VERSION ""

NS_ :

BS_:

BU_: INV DDC Master Charger
VAL_TABLE_ Prm_Mode 1 "Set Parameter value" 0 "Read back only" ;
VAL_TABLE_ PRM_SelVal 9 "Rectifier mode " 8 "Rectivier limit" 7 "Deadband" 6 "Shift preset value" 5 "Current limits" 4 "Output voltage limits" 3 "Input voltage limits" 2 "Voltage control" 1 "Current control" 0 "Empty" ;
VAL_TABLE_ DCDC_RectModeTab 2 "Rectifier Off" 1 "Rectifier On" 0 "Rectifiermode Auto" ;
VAL_TABLE_ DCDC_FaultSwOffTab 1 "Switchoff due to fault" 0 "Not switched off due to fault" ;
VAL_TABLE_ DCDC_FaultPresenTab 1 "Fault present" 0 "No fault present" ;
VAL_TABLE_ DCDC_SyncRectTab 1 "Sync Rectifier On" 0 "Sync Rectifier Off" ;
VAL_TABLE_ ULv_Plaus 1 "Low voltage plausible" 0 "Low voltage implausible" ;
VAL_TABLE_ TestMode 3 "Don't Care" 2 "HV test Mode" 1 "PCB Test Mode" 0 "Normal Mode" ;
VAL_TABLE_ SupplyState 1 "Supply OK" 0 "Supply not OK" ;
VAL_TABLE_ ShortCircuit 3 "Don't Care" 2 "Negative Short Circuit" 1 "Positive Short Circuit" 0 "No Short Circuit" ;
VAL_TABLE_ ReversePolarity 1 "Reverse Polarity" 0 "No reverse Polarity" ;
VAL_TABLE_ RangeCheck 1 "Ok" 0 "Not Ok" ;
VAL_TABLE_ OvrTempShutDown 1 "Shutdown due to overtemperature" 0 "No overtemperature" ;
VAL_TABLE_ OverVoltageShutDown 1 "Shutdown due to overvoltage" 0 "No overvoltage" ;
VAL_TABLE_ OverCurrentShutDown 1 "Shutdown due to overcurrent" 0 "No overcurrent" ;
VAL_TABLE_ OpMode 7 "Failure" 6 "Reserve4" 5 "Reserve3" 4 "Reserve2" 3 "Reserve1" 2 "Buck" 1 "Standby" 0 "Init" ;
VAL_TABLE_ InitFail_9Bit 511 "Failure" 510 "Init" ;
VAL_TABLE_ InitFail_11Bit 2047 "Failure" 2046 "Init" ;
VAL_TABLE_ InitFail_10Bit 1023 "Failure" 1022 "Init" ;
VAL_TABLE_ FullBridgeEnable 1 "Full Bridge Switched on" 0 "Full Bridge Switched off" ;
VAL_TABLE_ ErrorSupplyVoltage 1 "Error Supply Voltage" 0 "Supply Voltage O.K." ;
VAL_TABLE_ EnOutp 3 "EnLvOutBuck=1; EnLvOutBoost=1" 2 "EnLvOutBuck=1; EnLvOutBoost=0" 1 "EnLvOutBuck=0; EnLvOutBoost=1" 0 "EnLvOutBuck=0; EnLvOutBoost=0" ;
VAL_TABLE_ EnLvOut 1 "Active (closed)" 0 "Inactive (open)" ;
VAL_TABLE_ DesMode 3 "Reserve2" 2 "GoReset" 1 "Buck" 0 "Standby" ;
VAL_TABLE_ ControlMode 1 "Current Control active" 0 "Voltage Control active" ;
VAL_TABLE_ SucEnable 1 "turn SUC on" 0 "turn SUC off" ;
VAL_TABLE_ DCDCMode 2 "Steuerung_Vorgabewert" 1 "Regelung_Aktiv" 0 "Standby" ;

BO_ 3221225472 VECTOR__INDEPENDENT_SIG_MSG: 0 Vector__XXX
 SG_ PRM_Dummy4 : 0|16@1- (1,0) [0|0] "" Vector__XXX
 SG_ PRM_Dummy3 : 0|16@1- (1,0) [0|0] "" Vector__XXX
 SG_ StaMsgCntr : 0|8@1+ (1,0) [0|255] "" Vector__XXX
 SG_ PRM_enaSynRectOvlp : 0|8@1+ (1,0) [0|40] "setBit_to_enable_Fault" Vector__XXX
 SG_ PRM_numSynRectOvlp2 : 0|8@1+ (1,0) [0|40] "setBit_to_enable_Fault" Vector__XXX
 SG_ Parameter2 : 0|16@1- (1,0) [0|0] "" Vector__XXX
 SG_ Parameter1 : 0|16@1- (1,0) [0|0] "" Vector__XXX

BO_ 293 DDC_12: 8 DDC
 SG_ DDC_Suc_Fail : 27|1@1+ (1,0) [0|1] ""  INV
 SG_ DDC_IHv : 32|10@1+ (0.025,0) [0|25.575] "A"  INV
 SG_ DDC_UHv_Overvoltage : 26|1@1+ (1,0) [0|1] ""  INV
 SG_ DDC_UHv_Undervoltage : 25|1@1+ (1,0) [0|1] ""  INV
 SG_ DDC_HvOverCurrent : 24|1@1+ (1,0) [0|1] ""  INV
 SG_ DDC_RangeChk_VZK_UBat : 23|1@1+ (1,0) [0|1] ""  INV
 SG_ DDC_RangeChk_VZK_LoRng : 22|1@1+ (1,0) [0|1] ""  INV
 SG_ DDC_RangeChk_VZK_HiRng : 21|1@1+ (1,0) [0|1] ""  INV
 SG_ DDC_RangeChk_VZK_Gnd : 20|1@1+ (1,0) [0|1] ""  INV
 SG_ DDC_RangeChk_IZK_UBat : 19|1@1+ (1,0) [0|1] ""  INV
 SG_ DDC_RangeChk_IZK_LoRng : 18|1@1+ (1,0) [0|1] ""  INV
 SG_ DDC_RangeChk_IZK_HiRng : 17|1@1+ (1,0) [0|1] ""  INV
 SG_ DDC_RangeChk_IZK_Gnd : 16|1@1+ (1,0) [0|1] ""  INV
 SG_ DDC_RangeChk_VLV_UBat : 15|1@1+ (1,0) [0|1] ""  INV
 SG_ DDC_RangeChk_VLV_LoRng : 14|1@1+ (1,0) [0|1] ""  INV
 SG_ DDC_RangeChk_VLV_HiRng : 13|1@1+ (1,0) [0|1] ""  INV
 SG_ DDC_RangeChk_VLV_Gnd : 12|1@1+ (1,0) [0|1] ""  INV
 SG_ DDC_RangeChk_VHV_UBat : 11|1@1+ (1,0) [0|1] ""  INV
 SG_ DDC_RangeChk_VHV_LoRng : 10|1@1+ (1,0) [0|1] ""  INV
 SG_ DDC_RangeChk_VHV_HiRng : 9|1@1+ (1,0) [0|1] ""  INV
 SG_ DDC_RangeChk_VHV_Gnd : 8|1@1+ (1,0) [0|1] ""  INV
 SG_ DDC_RangeChk_ILV_UBat : 7|1@1+ (1,0) [0|1] ""  INV
 SG_ DDC_RangeChk_ILV_LoRng : 6|1@1+ (1,0) [0|1] ""  INV
 SG_ DDC_RangeChk_ILV_HiRng : 5|1@1+ (1,0) [0|1] ""  INV
 SG_ DDC_RangeChk_ILV_Gnd : 4|1@1+ (1,0) [0|1] ""  INV
 SG_ DDC_RangeChk_IHV_UBat : 3|1@1+ (1,0) [0|1] ""  INV
 SG_ DDC_RangeChk_IHV_LoRng : 2|1@1+ (1,0) [0|1] ""  INV
 SG_ DDC_RangeChk_IHV_HiRng : 1|1@1+ (1,0) [0|1] ""  INV
 SG_ DDC_RangeChk_IHV_Gnd : 0|1@1+ (1,0) [0|1] ""  INV

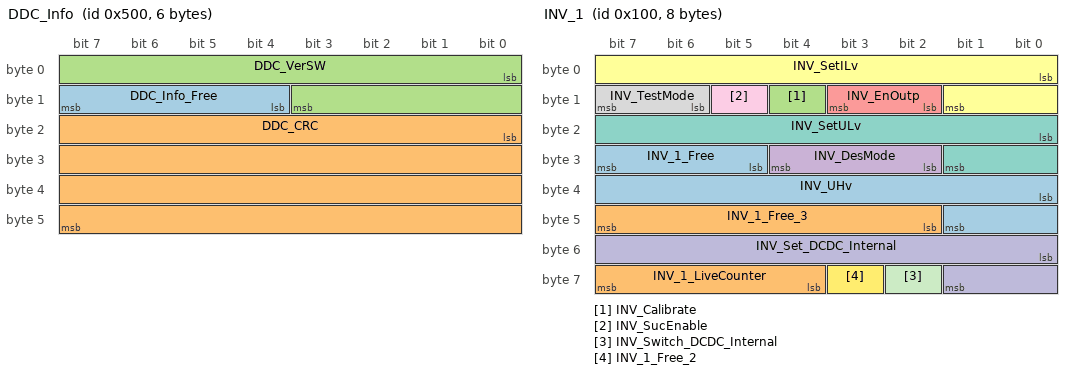
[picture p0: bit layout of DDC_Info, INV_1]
BO_ 1280 DDC_Info: 6 DDC
 SG_ DDC_Info_Free : 12|4@1+ (1,0) [0|15] ""  INV
 SG_ DDC_CRC : 16|32@1+ (1,0) [0|4294967295] ""  INV
 SG_ DDC_VerSW : 0|12@1+ (1,0) [0|4095] ""  INV

BO_ 256 INV_1: 8 INV
 SG_ INV_1_Free : 29|3@1+ (1,0) [0|7] ""  DDC
 SG_ INV_1_LiveCounter : 60|4@1+ (1,0) [0|15] ""  DDC
 SG_ INV_Calibrate : 12|1@1+ (1,0) [0|0] ""  DDC
 SG_ INV_DesMode : 26|3@1+ (1,0) [0|7] ""  DDC
 SG_ INV_EnOutp : 10|2@1+ (1,0) [0|3] ""  DDC
 SG_ INV_SetILv : 0|10@1+ (0.25,0) [0|255.75] "A"  DDC
 SG_ INV_SetULv : 16|10@1+ (0.015625,4) [4|19.984375] "V"  DDC
 SG_ INV_TestMode : 14|2@1+ (1,0) [0|3] ""  DDC
 SG_ INV_SucEnable : 13|1@1+ (1,0) [0|1] ""  DDC
 SG_ INV_Set_DCDC_Internal : 48|10@1+ (1,0) [0|1023] ""  DDC
 SG_ INV_Switch_DCDC_Internal : 58|1@1+ (1,0) [0|1] ""  DDC
 SG_ INV_1_Free_2 : 59|1@1+ (1,0) [0|1] ""  DDC
 SG_ INV_UHv : 32|10@1+ (0.5,0) [0|511.5] ""  DDC
 SG_ INV_1_Free_3 : 42|6@1+ (1,0) [0|63] ""  DDC

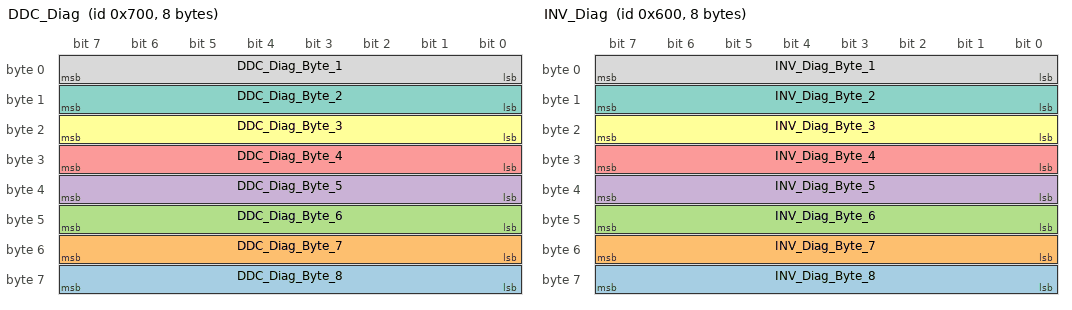
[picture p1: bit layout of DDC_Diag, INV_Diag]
BO_ 1792 DDC_Diag: 8 DDC
 SG_ DDC_Diag_Byte_8 : 56|8@1+ (1,0) [0|255] ""  INV
 SG_ DDC_Diag_Byte_7 : 48|8@1+ (1,0) [0|255] ""  INV
 SG_ DDC_Diag_Byte_6 : 40|8@1+ (1,0) [0|255] ""  INV
 SG_ DDC_Diag_Byte_5 : 32|8@1+ (1,0) [0|255] ""  INV
 SG_ DDC_Diag_Byte_4 : 24|8@1+ (1,0) [0|255] ""  INV
 SG_ DDC_Diag_Byte_3 : 16|8@1+ (1,0) [0|255] ""  INV
 SG_ DDC_Diag_Byte_2 : 8|8@1+ (1,0) [0|255] ""  INV
 SG_ DDC_Diag_Byte_1 : 0|8@1+ (1,0) [0|255] ""  INV

BO_ 1536 INV_Diag: 8 INV
 SG_ INV_Diag_Byte_8 : 56|8@1+ (1,0) [0|255] ""  DDC
 SG_ INV_Diag_Byte_7 : 48|8@1+ (1,0) [0|255] ""  DDC
 SG_ INV_Diag_Byte_6 : 40|8@1+ (1,0) [0|255] ""  DDC
 SG_ INV_Diag_Byte_5 : 32|8@1+ (1,0) [0|255] ""  DDC
 SG_ INV_Diag_Byte_4 : 24|8@1+ (1,0) [0|255] ""  DDC
 SG_ INV_Diag_Byte_3 : 16|8@1+ (1,0) [0|255] ""  DDC
 SG_ INV_Diag_Byte_2 : 8|8@1+ (1,0) [0|255] ""  DDC
 SG_ INV_Diag_Byte_1 : 0|8@1+ (1,0) [0|255] ""  DDC

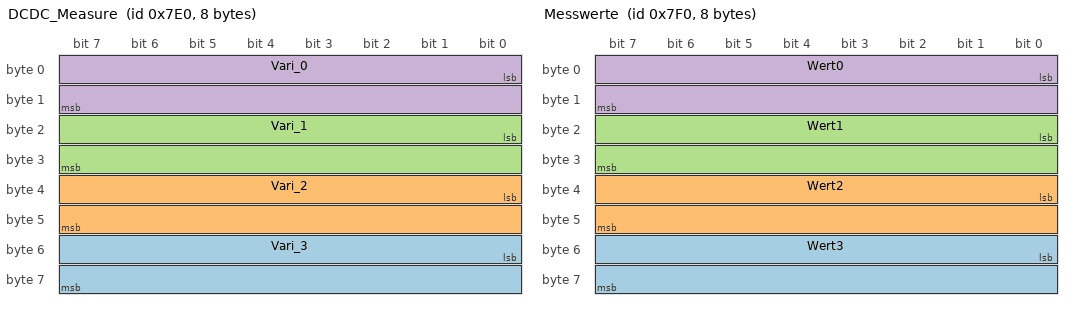
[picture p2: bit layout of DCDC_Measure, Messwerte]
BO_ 2016 DCDC_Measure: 8 Vector__XXX
 SG_ Vari_3 : 48|16@1- (1,0) [0|0] "" Vector__XXX
 SG_ Vari_2 : 32|16@1- (1,0) [0|0] "" Vector__XXX
 SG_ Vari_1 : 16|16@1- (1,0) [0|0] "" Vector__XXX
 SG_ Vari_0 : 0|16@1- (1,0) [0|0] "" Vector__XXX

BO_ 288 DDC_11: 8 DDC
 SG_ DDC_LiveCounter_Error : 46|1@1+ (1,0) [0|1] ""  INV
 SG_ DDC_CAN_Tout : 45|1@1+ (1,0) [0|1] ""  INV
 SG_ DDC_Int_Fail_Cause : 47|1@1+ (1,0) [0|1] ""  INV
 SG_ DDC_DCDC_Shutdown : 43|2@1+ (1,0) [0|3] ""  INV
 SG_ DDC_FB_Overload : 42|1@1+ (1,0) [0|1] ""  INV
 SG_ DDC_ControlMode : 62|1@1+ (1,0) [0|1] ""  INV
 SG_ DDC_HV_Serial_Data_ok : 30|1@1+ (1,0) [0|1] ""  INV
 SG_ DDC_LnkOverVoltage : 63|1@1+ (1,0) [0|1] ""  INV
 SG_ DDC_LV_Serial_Data_ok : 29|1@1+ (1,0) [0|1] ""  INV
 SG_ DDC_ScrewExist : 61|1@1+ (1,0) [0|1] ""  INV
 SG_ DDC_OvrTempShutDown : 60|1@1+ (1,0) [0|1] ""  INV
 SG_ DDC_ULnk : 32|10@1+ (0.5,0) [0|511.5] "V"  INV
 SG_ DDC_SetULv : 16|10@1+ (0.015625,0) [0|15.984375] "V"  INV
 SG_ DDC_SetILv : 0|10@1+ (0.25,0) [0|255.75] "A"  INV
 SG_ DDC_ReversePolarity : 31|1@1+ (1,0) [0|1] ""  INV
 SG_ DDC_ResetFinish : 28|1@1+ (1,0) [0|1] ""  INV
 SG_ DDC_LV_S8_13V : 11|1@1+ (1,0) [0|1] ""  INV
 SG_ DDC_LV_S7_13V : 10|1@1+ (1,0) [0|1] ""  INV
 SG_ DDC_LV_3V3 : 13|1@1+ (1,0) [0|1] ""  INV
 SG_ DDC_LV_13V : 12|1@1+ (1,0) [0|1] ""  INV
 SG_ DDC_ILnk : 48|10@1+ (0.025,0) [0|25.575] "A"  INV
 SG_ DDC_HV_3V3 : 15|1@1+ (1,0) [0|1] ""  INV
 SG_ DDC_HV_13V_FB : 14|1@1+ (1,0) [0|1] ""  INV
 SG_ DDC_HV_13V_Boost : 26|1@1+ (1,0) [0|1] ""  INV
 SG_ DDC_HV_13V : 27|1@1+ (1,0) [0|1] ""  INV
 SG_ DDC_FBEnable : 58|1@1+ (1,0) [0|1] ""  INV
 SG_ DDC_SucEnable : 59|1@1+ (1,0) [0|1] ""  INV

BO_ 2032 Messwerte: 8 Vector__XXX
 SG_ Wert3 : 48|16@1- (1,0) [0|0] "" Vector__XXX
 SG_ Wert2 : 32|16@1- (1,0) [0|0] "" Vector__XXX
 SG_ Wert1 : 16|16@1- (1,0) [0|0] "" Vector__XXX
 SG_ Wert0 : 0|16@1- (1,0) [0|0] "" Vector__XXX

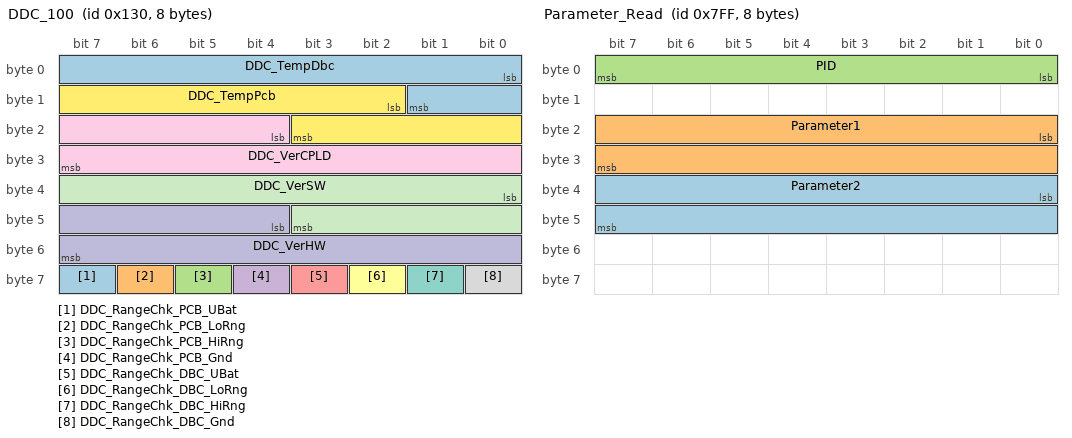
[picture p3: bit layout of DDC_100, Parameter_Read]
BO_ 304 DDC_100: 8 DDC
 SG_ DDC_RangeChk_PCB_UBat : 63|1@1+ (1,0) [0|1] ""  INV
 SG_ DDC_RangeChk_PCB_LoRng : 62|1@1+ (1,0) [0|1] ""  INV
 SG_ DDC_RangeChk_PCB_HiRng : 61|1@1+ (1,0) [0|1] ""  INV
 SG_ DDC_RangeChk_PCB_Gnd : 60|1@1+ (1,0) [0|1] ""  INV
 SG_ DDC_RangeChk_DBC_UBat : 59|1@1+ (1,0) [0|1] ""  INV
 SG_ DDC_RangeChk_DBC_LoRng : 58|1@1+ (1,0) [0|1] ""  INV
 SG_ DDC_RangeChk_DBC_HiRng : 57|1@1+ (1,0) [0|1] ""  INV
 SG_ DDC_RangeChk_DBC_Gnd : 56|1@1+ (1,0) [0|1] ""  INV
 SG_ DDC_VerCPLD : 20|12@1+ (1,0) [0|4095] ""  INV
 SG_ DDC_VerHW : 44|12@1+ (1,0) [0|4095] ""  INV
 SG_ DDC_VerSW : 32|12@1+ (1,0) [0|4095] ""  INV
 SG_ DDC_TempPcb : 10|10@1+ (0.25,-50) [-50|205.75] "°C"  INV
 SG_ DDC_TempDbc : 0|10@1+ (0.25,-50) [-50|205.75] "°C"  INV

BO_ 2047 Parameter_Read: 8 Vector__XXX
 SG_ Parameter2 : 32|16@1- (1,0) [0|0] "" Vector__XXX
 SG_ Parameter1 : 16|16@1- (1,0) [0|0] "" Vector__XXX
 SG_ PID : 0|8@1+ (1,0) [0|0] "" Vector__XXX

BO_ 2046 Parameter_Write: 8 Vector__XXX
 SG_ PRM_frqJitter m10 : 16|16@1- (1,0) [0|10000] "Hz" Vector__XXX
 SG_ PRM_ampJitter m10 : 32|16@1- (1,0) [0|10] "%" Vector__XXX
 SG_ PRM_Rect_Mode m9 : 16|16@1- (1,0) [-32768|32767] "" Vector__XXX
 SG_ PRM_PhaseShiftDCDC m6 : 16|16@1- (0.02442,0) [0|100] "%" Vector__XXX
 SG_ PRM_uOutMin m4 : 16|16@1- (0.03125,0) [0|600] "V" Vector__XXX
 SG_ PRM_uOutMax m4 : 32|16@1- (0.03125,0) [0|600] "V" Vector__XXX
 SG_ PRM_uInputMin m3 : 32|16@1- (0.03125,0) [0|600] "V" Vector__XXX
 SG_ PRM_uInputMax m3 : 16|16@1- (0.03125,0) [0|600] "V" Vector__XXX
 SG_ PRM_numSynRectOfs m6 : 32|16@1+ (1,0) [0|65535] "ticks" Vector__XXX
 SG_ PRM_numDeadOnBase m7 : 16|16@1- (8.3,0) [-271974.4|271966.1] "ns" Vector__XXX
 SG_ PRM_numDeadOffBase m7 : 32|16@1- (8.3,0) [-271974.4|271966.1] "ns" Vector__XXX
 SG_ PRM_iHVPeakDCDC m5 : 16|16@1- (0.00564,0) [0|20] "A" Vector__XXX
 SG_ PRM_iOutMax m5 : 32|16@1- (0.003906,0) [0|20] "A" Vector__XXX
 SG_ PRM_Curr_Rect_On m8 : 16|16@1- (0.003906,0) [0|100] "A" Vector__XXX
 SG_ PRM_Curr_Rect_Off m8 : 32|16@1- (0.003906,0) [0|100] "A" Vector__XXX
 SG_ PRM_Curr_Peak_Ofs m9 : 32|16@1- (0.0009765,0) [-31.997952|31.9969755] "A" Vector__XXX
 SG_ PRM_facHVDCDCVltgCtlProp m2 : 16|16@1- (0.00024414,0) [-7.99997952|7.99973538] "AperV" Vector__XXX
 SG_ PRM_facHVDCDCVltgCtlIntg m2 : 32|16@1- (0.00024414,0) [-7.99997952|7.99973538] "AperVms" Vector__XXX
 SG_ PRM_facHVDCDCCurrCtlProp m1 : 16|16@1- (0.00024414,0) [-7.99997952|7.99973538] "AperA" Vector__XXX
 SG_ PRM_facHVDCDCCurrCtlIntg m1 : 32|16@1- (0.00024414,0) [-7.99997952|7.99973538] "AperAms" Vector__XXX
 SG_ PRM_Dummy2 m0 : 32|16@1- (1,0) [0|0] "" Vector__XXX
 SG_ PRM_Dummy1 m0 : 16|16@1- (1,0) [0|0] "" Vector__XXX
 SG_ ParameterMode : 8|8@1+ (1,0) [0|0] "" Vector__XXX
 SG_ PID M : 0|8@1+ (1,0) [0|0] "" Vector__XXX

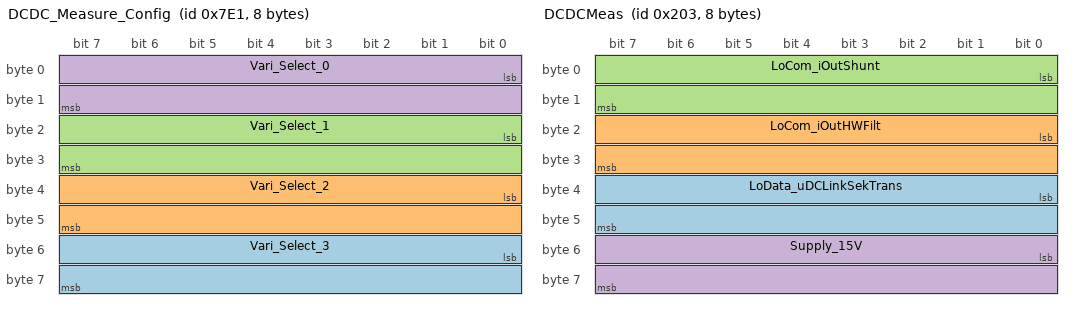
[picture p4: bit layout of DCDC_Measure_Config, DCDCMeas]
BO_ 2017 DCDC_Measure_Config: 8 Master
 SG_ Vari_Select_3 : 48|16@1+ (1,0) [0|0] "" Vector__XXX
 SG_ Vari_Select_2 : 32|16@1+ (1,0) [0|0] "" Vector__XXX
 SG_ Vari_Select_1 : 16|16@1+ (1,0) [0|0] "" Vector__XXX
 SG_ Vari_Select_0 : 0|16@1+ (1,0) [0|0] "" Vector__XXX

BO_ 515 DCDCMeas: 8 Charger
 SG_ LoData_uDCLinkSekTrans : 32|16@1- (0.03125,0) [-1024|1023.96875] "V" Vector__XXX
 SG_ LoCom_iOutHWFilt : 16|16@1- (0.0078125,0) [-256|255.9921875] "A" Vector__XXX
 SG_ LoCom_iOutShunt : 0|16@1- (0.0078125,0) [-256|255.9921875] "A" Vector__XXX
 SG_ Supply_15V : 48|16@1- (0.0089285714285714,0) [-292.57142857143|292.5625] "V" Vector__XXX

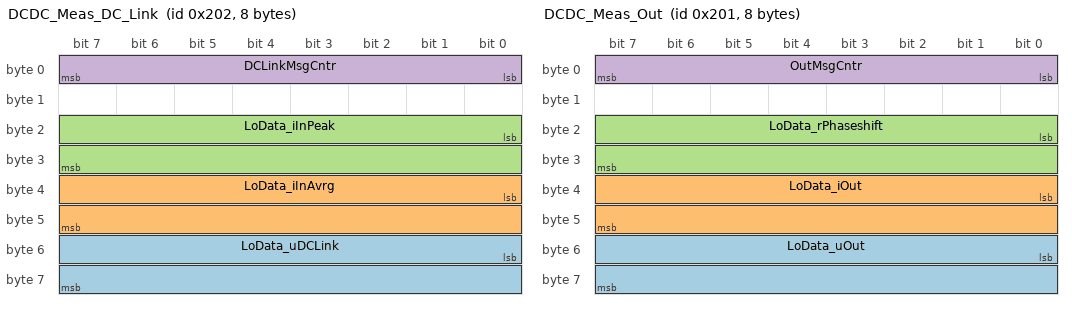
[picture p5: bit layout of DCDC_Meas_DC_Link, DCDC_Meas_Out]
BO_ 514 DCDC_Meas_DC_Link: 8 Charger
 SG_ LoData_uDCLink : 48|16@1- (0.03125,0) [-1024|1023.96875] "V" Vector__XXX
 SG_ LoData_iInAvrg : 32|16@1- (0.0009765625,0) [-32|31.9990234375] "A" Vector__XXX
 SG_ LoData_iInPeak : 16|16@1- (0.0009765625,0) [-32|31.9990234375] "A" Vector__XXX
 SG_ DCLinkMsgCntr : 0|8@1+ (1,0) [0|255] "" Vector__XXX

BO_ 513 DCDC_Meas_Out: 8 Charger
 SG_ LoData_uOut : 48|16@1- (0.016,0) [-524.288|524.272] "V" Vector__XXX
 SG_ LoData_iOut : 32|16@1- (0.0078125,0) [-256|255.9921875] "A" Vector__XXX
 SG_ LoData_rPhaseshift : 16|16@1- (0.0244140625,0) [-800|799.9755859375] "%" Vector__XXX
 SG_ OutMsgCntr : 0|8@1+ (1,0) [0|255] "" Vector__XXX

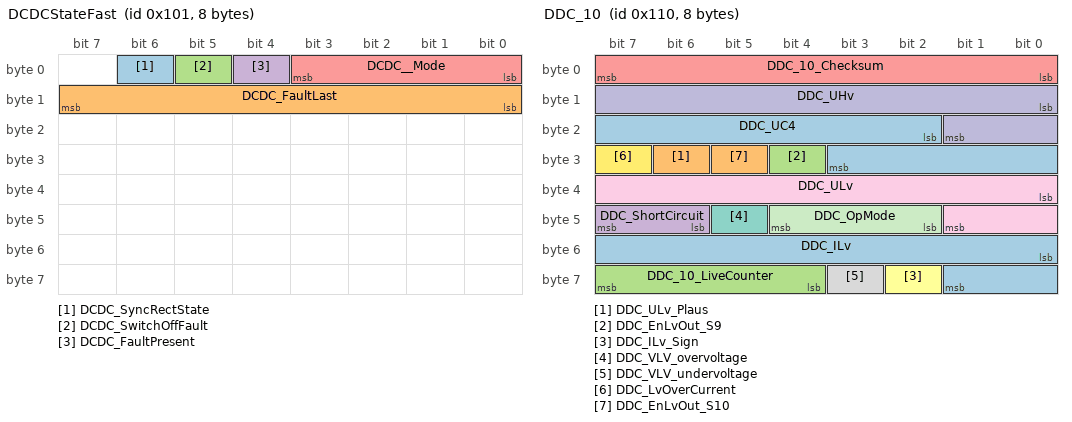
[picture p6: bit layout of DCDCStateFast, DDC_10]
BO_ 257 DCDCStateFast: 8 Charger
 SG_ DCDC_SyncRectState : 6|1@1+ (1,0) [0|0] "" Vector__XXX
 SG_ DCDC_FaultLast : 8|8@1- (1,0) [0|0] "" Vector__XXX
 SG_ DCDC_SwitchOffFault : 5|1@1+ (1,0) [0|0] "" Vector__XXX
 SG_ DCDC_FaultPresent : 4|1@1+ (1,0) [0|0] "" Vector__XXX
 SG_ DCDC__Mode : 0|4@1+ (1,0) [0|15] "" Vector__XXX

BO_ 272 DDC_10: 8 DDC
 SG_ DDC_UC4 : 18|10@1+ (0.03125,0) [0|31.96875] "V"  INV
 SG_ DDC_ULv_Plaus : 30|1@1+ (1,0) [0|1] ""  INV
 SG_ DDC_EnLvOut_S9 : 28|1@1+ (1,0) [0|1] ""  INV
 SG_ DDC_ShortCircuit : 46|2@1+ (1,0) [0|3] ""  INV
 SG_ DDC_10_Checksum : 0|8@1+ (1,0) [0|255] ""  INV
 SG_ DDC_ILv_Sign : 58|1@1+ (1,0) [0|1] ""  INV
 SG_ DDC_VLV_overvoltage : 45|1@1+ (1,0) [0|1] ""  INV
 SG_ DDC_VLV_undervoltage : 59|1@1+ (1,0) [0|1] ""  INV
 SG_ DDC_ULv : 32|10@1+ (0.03125,0) [0|31.96875] "V"  INV
 SG_ DDC_UHv : 8|10@1+ (0.5,0) [0|511.5] "V"  INV
 SG_ DDC_OpMode : 42|3@1+ (1,0) [0|7] ""  INV
 SG_ DDC_LvOverCurrent : 31|1@1+ (1,0) [0|1] ""  INV
 SG_ DDC_ILv : 48|10@1+ (0.25,0) [0|255.75] "A"  INV
 SG_ DDC_EnLvOut_S10 : 29|1@1+ (1,0) [0|1] ""  INV
 SG_ DDC_10_LiveCounter : 60|4@1+ (1,0) [0|15] ""  INV

EV_ HV_Act_Val_In: 0 [0|1] "V" 0 1 DUMMY_NODE_VECTOR0 Vector__XXX;

EV_ UMG_DDC_EnLvOut: 0 [0|1] "" 0 2 DUMMY_NODE_VECTOR0 Vector__XXX;

CM_ BO_ 3221225472 "This is a message for not used signals, created by Vector CANdb++ DBC OLE DB Provider.";
CM_ SG_ 293 DDC_Suc_Fail "Specifies whether Step Up Converter is malfunctioning.";
CM_ SG_ 293 DDC_IHv "Reports the actual current on the HV side (shunt RS2).";
CM_ SG_ 293 DDC_UHv_Overvoltage "indicates status of VZK RangeCheck
detects connection to Ground";
CM_ SG_ 293 DDC_UHv_Undervoltage "indicates status of VZK RangeCheck
detects connection to Ground";
CM_ SG_ 293 DDC_HvOverCurrent "Indicates an over current on the HV side of the DC/DC-converter";
CM_ SG_ 293 DDC_RangeChk_VZK_UBat "indicates status of VZK RangeCheck
detects connection to U Batt (supply voltage)";
CM_ SG_ 293 DDC_RangeChk_VZK_LoRng "indicates status of VZK RangeCheck
detects physical values which are below the feasible range";
CM_ SG_ 293 DDC_RangeChk_VZK_HiRng "indicates status of VZK RangeCheck
detects physical values which are above the feasible range";
CM_ SG_ 293 DDC_RangeChk_VZK_Gnd "indicates status of VZK RangeCheck
detects connection to Ground";
CM_ SG_ 293 DDC_RangeChk_IZK_UBat "indicates status of IRS3 RangeCheck
detects connection to U Batt (supply voltage)";
CM_ SG_ 293 DDC_RangeChk_IZK_LoRng "indicates status of IRS3 RangeCheck
detects physical values which are below the feasible range";
CM_ SG_ 293 DDC_RangeChk_IZK_HiRng "indicates status of IRS3 RangeCheck
detects physical values which are above the feasible range";
CM_ SG_ 293 DDC_RangeChk_IZK_Gnd "indicates status of IRS3 RangeCheck
detects connection to Ground";
CM_ SG_ 293 DDC_RangeChk_VLV_UBat "indicates status of VLV RangeCheck
detects connection to U Batt (supply voltage)";
CM_ SG_ 293 DDC_RangeChk_VLV_LoRng "indicates status of VLV RangeCheck
detects physical values which are below the feasible range";
CM_ SG_ 293 DDC_RangeChk_VLV_HiRng "indicates status of VLV RangeCheck
detects physical values which are above the feasible range";
CM_ SG_ 293 DDC_RangeChk_VLV_Gnd "indicates status of VLV RangeCheck
detects connection to Ground";
CM_ SG_ 293 DDC_RangeChk_VHV_UBat "indicates status of VHV RangeCheck
detects connection to U Batt (supply voltage)";
CM_ SG_ 293 DDC_RangeChk_VHV_LoRng "indicates status of VHV RangeCheck
detects physical values which are below the feasible range";
CM_ SG_ 293 DDC_RangeChk_VHV_HiRng "indicates status of VHV RangeCheck
detects physical values which are above the feasible range";
CM_ SG_ 293 DDC_RangeChk_VHV_Gnd "indicates status of VHV RangeCheck
detects connection to Ground";
CM_ SG_ 293 DDC_RangeChk_ILV_UBat "indicates status of ILV RangeCheck
detects connection to U Batt (supply voltage)";
CM_ SG_ 293 DDC_RangeChk_ILV_LoRng "indicates status of ILV RangeCheck
detects physical values which are below the feasible range";
CM_ SG_ 293 DDC_RangeChk_ILV_HiRng "indicates status of ILV RangeCheck
detects physical values which are above the feasible range";
CM_ SG_ 293 DDC_RangeChk_ILV_Gnd "indicates status of ILV RangeCheck
detects connection to Ground";
CM_ SG_ 293 DDC_RangeChk_IHV_UBat "indicates status of IHV RangeCheck
detects connection to U Batt (supply voltage)";
CM_ SG_ 293 DDC_RangeChk_IHV_LoRng "indicates status of IHV RangeCheck
detects physical values which are below the feasible range";
CM_ SG_ 293 DDC_RangeChk_IHV_HiRng "indicates status of IHV RangeCheck
detects physical values which are above the feasible range";
CM_ SG_ 293 DDC_RangeChk_IHV_Gnd "indicates status of IHV RangeCheck
detects connection to Ground";
CM_ SG_ 1280 DDC_CRC "CRC checksum of µC LV software";
CM_ SG_ 1280 DDC_VerSW "2 MSB bits (Bits 11-10) :
00 - B sample
01 - C sample
10 - D sample
11 - Not used
Example :
Version Number B 1.0.0 -> 00 001 000 0000
                          C 3.2.5 -> 01 011 010 0101
";
CM_ SG_ 256 INV_1_Free "Free for DCDC Internal Testing";
CM_ SG_ 256 INV_1_LiveCounter "To check internal communication
Every new message should increment this counter by 1 and wrap to '0' when counter is equal to 15";
CM_ SG_ 256 INV_Calibrate "Calibrate Measurement Signals based on special Working Point

0 to 1- Calibrate

1 to 0 - Don't Care
";
CM_ SG_ 256 INV_DesMode "Desired operating mode the DC/DC converter.";
CM_ SG_ 256 INV_EnOutp "Used to control the transistors S9 (ENLVOUTBOOST) and S10 (ENLVOUTBUCK).";
CM_ SG_ 256 INV_SetILv "Current limit on the LV side.";
CM_ SG_ 256 INV_SetULv "Set point voltage on the LV side.";
CM_ SG_ 256 INV_TestMode "To switch between different modes (Normal Mode, Test Mode PCB, Test Mode HV)
00 - Normal Mode
01 - PCB Test Mode
10 - HV test Mode
11 - Don't Care";
CM_ SG_ 256 INV_SucEnable "activate Step Up Converter";
CM_ SG_ 256 INV_Set_DCDC_Internal "Current limit on the LV side.";
CM_ SG_ 256 INV_Switch_DCDC_Internal "0 - Manual Calculation
1 - Use Valiue coming over CAN";
CM_ SG_ 256 INV_1_Free_2 "Free for DCDC Internal Testing";
CM_ SG_ 256 INV_UHv "Inverter reports the actual voltage on the HV side";
CM_ SG_ 256 INV_1_Free_3 "Free for DCDC Internal Testing";
CM_ SG_ 1792 DDC_Diag_Byte_8 "Diag Frame byte8";
CM_ SG_ 1792 DDC_Diag_Byte_7 "Diag Frame byte7";
CM_ SG_ 1792 DDC_Diag_Byte_6 "Diag Frame byte6";
CM_ SG_ 1792 DDC_Diag_Byte_5 "Diag Frame byte5";
CM_ SG_ 1792 DDC_Diag_Byte_4 "Diag Frame byte4";
CM_ SG_ 1792 DDC_Diag_Byte_3 "Diag Frame byte3";
CM_ SG_ 1792 DDC_Diag_Byte_2 "Diag Frame byte2";
CM_ SG_ 1792 DDC_Diag_Byte_1 "Diag Frame byte1";
CM_ SG_ 1536 INV_Diag_Byte_8 "Diag Frame byte8";
CM_ SG_ 1536 INV_Diag_Byte_7 "Diag Frame byte7";
CM_ SG_ 1536 INV_Diag_Byte_6 "Diag Frame byte6";
CM_ SG_ 1536 INV_Diag_Byte_5 "Diag Frame byte5";
CM_ SG_ 1536 INV_Diag_Byte_4 "Diag Frame byte4";
CM_ SG_ 1536 INV_Diag_Byte_3 "Diag Frame byte3";
CM_ SG_ 1536 INV_Diag_Byte_2 "Diag Frame byte2";
CM_ SG_ 1536 INV_Diag_Byte_1 "Diag Frame byte1";
CM_ SG_ 288 DDC_LiveCounter_Error "indicates live counter error in INV_1";
CM_ SG_ 288 DDC_CAN_Tout "indicates CAN C time out reported by DCDC converter";
CM_ SG_ 288 DDC_Int_Fail_Cause "Specifies Internal faliure causes for DCDC. At present it is not used. In future value description table is added according to needs";
CM_ SG_ 288 DDC_DCDC_Shutdown "Specifies whether LVuC, LV CPLD or HV CPLD detected failure and switched failure/standby mode";
CM_ SG_ 288 DDC_FB_Overload "Specifies whether FullBridge is overloaded or not";
CM_ SG_ 288 DDC_ControlMode "Indicates whether the DC/DC-converter operates in current regulation or in voltage regulation.";
CM_ SG_ 288 DDC_HV_Serial_Data_ok "Indicates state of serial data connection between LV CPLD and HV CPLD for HV in HV CPLD.";
CM_ SG_ 288 DDC_LnkOverVoltage "Indicates an overvoltage in the link circuit.";
CM_ SG_ 288 DDC_LV_Serial_Data_ok "Indicates state of serial data connection between LV CPLD and HV CPLD in LV CPLD.";
CM_ SG_ 288 DDC_ScrewExist "Screw state";
CM_ SG_ 288 DDC_OvrTempShutDown "Indicates an shut down due to overtemperature.";
CM_ SG_ 288 DDC_ULnk "Reports the actual voltage in the link circuit (capacitor C2).";
CM_ SG_ 288 DDC_SetULv "Reports the acutal set point voltage on the LV side.";
CM_ SG_ 288 DDC_SetILv "Reports the actual current limit on the LV side.";
CM_ SG_ 288 DDC_ReversePolarity "indicates status fo reverse Polarity";
CM_ SG_ 288 DDC_ResetFinish "indicates action described by Reset Diag is completed
0 to 1 - Finished
1 to 0 - After 10 ms of Transmit value of '1'";
CM_ SG_ 288 DDC_LV_S8_13V "indicates status of LV S8 13V Power Supply";
CM_ SG_ 288 DDC_LV_S7_13V "indicates status of LV S7 13V Power Supply";
CM_ SG_ 288 DDC_LV_3V3 "indicates status of LV 3.3V Power Supply";
CM_ SG_ 288 DDC_LV_13V "indicates status of LV 13V Power Supply";
CM_ SG_ 288 DDC_ILnk "Reports the actual current in the link circuit (shunt RS3).";
CM_ SG_ 288 DDC_HV_3V3 "indicates status of HV 3.3V Power Supply";
CM_ SG_ 288 DDC_HV_13V_FB "indicates status of Full Bridge Power Supply";
CM_ SG_ 288 DDC_HV_13V_Boost "indicates status of Boost Power Supply";
CM_ SG_ 288 DDC_HV_13V "indicates status of HV 13V Power Supply";
CM_ SG_ 288 DDC_FBEnable "indicates status of Full Bridge";
CM_ SG_ 288 DDC_SucEnable "indicates state of Step Up Converter";
CM_ SG_ 304 DDC_RangeChk_PCB_UBat "Signal Range Check of PCB-Temperature
detects connection to U Batt (supply voltage)";
CM_ SG_ 304 DDC_RangeChk_PCB_LoRng "Signal Range Check of PCB-Temperature
detects physical values which are below the feasible range";
CM_ SG_ 304 DDC_RangeChk_PCB_HiRng "Signal Range Check of PCB-Temperature
detects physical values which are above the feasible range";
CM_ SG_ 304 DDC_RangeChk_PCB_Gnd "Signal Range Check of PCB-Temperature";
CM_ SG_ 304 DDC_RangeChk_DBC_UBat "Signal Range Check of DBC-Temperature
detects connection to U Batt (supply voltage)";
CM_ SG_ 304 DDC_RangeChk_DBC_LoRng "Signal Range Check of DBC-Temperature
detects physical values which are below the feasible range";
CM_ SG_ 304 DDC_RangeChk_DBC_HiRng "Signal Range Check of DBC-Temperature
detects physical values which are above the feasible range";
CM_ SG_ 304 DDC_RangeChk_DBC_Gnd "Signal Range Check of DBC-Temperature
detects connection to Ground";
CM_ SG_ 304 DDC_VerCPLD "2 MSB bits (Bits 11-10) :
00 - B sample
01 - C sample
10 - D sample
11 - Not used
Example :
Version Number B 1.0.0 -> 00 001 000 0000
                          C 3.2.5 -> 01 011 010 0101
";
CM_ SG_ 304 DDC_VerHW "2 MSB bits (Bits 11-10) :
00 - B sample
01 - C sample
10 - D sample
11 - Not used
Example :
Version Number B 1.0.0 -> 00 001 000 0000
                          C 3.2.5 -> 01 011 010 0101
";
CM_ SG_ 304 DDC_VerSW "2 MSB bits (Bits 11-10) :
00 - B sample
01 - C sample
10 - D sample
11 - Not used
Example :
Version Number B 1.0.0 -> 00 001 000 0000
                          C 3.2.5 -> 01 011 010 0101
";
CM_ SG_ 304 DDC_TempPcb "Reports the actual temperature of the PCB sensor.";
CM_ SG_ 304 DDC_TempDbc "Reports the actual temperature of the DBC sensor.";
CM_ SG_ 272 DDC_UC4 "Reports the actual voltage on C4 capacitor.";
CM_ SG_ 272 DDC_ULv_Plaus "0 - low voltages implausible to each other
1 - low  voltages plausible to each other";
CM_ SG_ 272 DDC_EnLvOut_S9 "Reports the status of the transistors S9.";
CM_ SG_ 272 DDC_ShortCircuit "indicates status of Short Circuit ";
CM_ SG_ 272 DDC_10_Checksum "Checksum due to safety relevant. Calculation is done in the following way

DCDC:
Byte2 XOR Byte3 ... XOR Byte8 XOR 0x11 = checksum

TriCore:
Byte2 XOR Byte3 ... XOR Byte8 XOR checksum == 0x11

0x11 is derived from the message ID of DDC_10";
CM_ SG_ 272 DDC_ILv_Sign "Specifies whether low side current is positive or negative";
CM_ SG_ 272 DDC_VLV_overvoltage "State of overvoltage detection on LV side";
CM_ SG_ 272 DDC_VLV_undervoltage "State of undervoltage detection on LV side";
CM_ SG_ 272 DDC_ULv "Reports the actual voltage on the LV side.";
CM_ SG_ 272 DDC_UHv "Reports the actual voltage on the HV side.";
CM_ SG_ 272 DDC_OpMode "Reports the actual operating mode of the DC/DC software in the µC.";
CM_ SG_ 272 DDC_LvOverCurrent "Indicates on over current on the LV side.";
CM_ SG_ 272 DDC_ILv "Reports the actual current on the LV side of the DC/DC-converter.";
CM_ SG_ 272 DDC_EnLvOut_S10 "Reports the status of the transistors S10. ";
BA_DEF_ BO_  "GenMsgILSupport" ENUM  "No","Yes";
BA_DEF_  "NmBaseAddress" HEX 1024 1087;
BA_DEF_  "BusType" STRING ;
BA_DEF_  "GenNWMApBusSleep" STRING ;
BA_DEF_  "GenNWMApCanNormal" STRING ;
BA_DEF_  "GenNWMApCanOff" STRING ;
BA_DEF_  "GenNWMApCanOn" STRING ;
BA_DEF_  "GenNWMApCanSleep" STRING ;
BA_DEF_  "GenNWMApCanWakeUp" STRING ;
BA_DEF_  "GenNWMGotoMode_Awake" STRING ;
BA_DEF_  "GenNWMGotoMode_BusSleep" STRING ;
BA_DEF_  "GenNWMTalkNM" STRING ;
BA_DEF_ BO_  "GenMsgCycleTime" INT 2 50000;
BA_DEF_ BO_  "GenMsgDelayTime" INT 1 1000;
BA_DEF_ BO_  "GenMsgNrOfRepetitions" INT 1 999999;
BA_DEF_ BO_  "GenMsgSendType" ENUM  "cyclic","spontaneous","cyclicIfActive","spontaneousWithDelay","cyclicAndSpontaneous","cyclicAndSpontaneousWithDelay","spontaneousWithRepetition","cyclicIfActiveAndSpontaneousWD";
BA_DEF_ SG_  "GenSigStartValue" FLOAT 0 1215752192;
BA_DEF_  "GenEnvVarEndingDsp" STRING ;
BA_DEF_  "GenEnvVarEndingSnd" STRING ;
BA_DEF_  "GenEnvVarPrefix" STRING ;
BA_DEF_ SG_  "GenSigEnvVarType" ENUM  "int","float","undef";
BA_DEF_DEF_  "GenMsgILSupport" "Yes";
BA_DEF_DEF_  "NmBaseAddress" 1024;
BA_DEF_DEF_  "BusType" "CAN";
BA_DEF_DEF_  "GenNWMApBusSleep" "apBusSleep()";
BA_DEF_DEF_  "GenNWMApCanNormal" "apCanNormal()";
BA_DEF_DEF_  "GenNWMApCanOff" "apCanOff()";
BA_DEF_DEF_  "GenNWMApCanOn" "apCanOn()";
BA_DEF_DEF_  "GenNWMApCanSleep" "apCanSleep()";
BA_DEF_DEF_  "GenNWMApCanWakeUp" "apCanWakeUp()";
BA_DEF_DEF_  "GenNWMGotoMode_Awake" "GotoMode_Awake()";
BA_DEF_DEF_  "GenNWMGotoMode_BusSleep" "GotoMode_BusSleep()";
BA_DEF_DEF_  "GenNWMTalkNM" "TalkNM()";
BA_DEF_DEF_  "GenMsgCycleTime" 100;
BA_DEF_DEF_  "GenMsgDelayTime" 1;
BA_DEF_DEF_  "GenMsgNrOfRepetitions" 1;
BA_DEF_DEF_  "GenMsgSendType" "";
BA_DEF_DEF_  "GenSigStartValue" 0;
BA_DEF_DEF_  "GenEnvVarEndingDsp" "Dsp_";
BA_DEF_DEF_  "GenEnvVarEndingSnd" "_";
BA_DEF_DEF_  "GenEnvVarPrefix" "Env";
BA_DEF_DEF_  "GenSigEnvVarType" "undef";
BA_ "GenMsgCycleTime" BO_ 293 10;
BA_ "GenMsgSendType" BO_ 293 0;
BA_ "GenMsgSendType" BO_ 256 0;
BA_ "GenMsgCycleTime" BO_ 256 10;
BA_ "GenMsgCycleTime" BO_ 1792 2;
BA_ "GenMsgSendType" BO_ 1792 0;
BA_ "GenMsgCycleTime" BO_ 1536 2;
BA_ "GenMsgSendType" BO_ 1536 0;
BA_ "GenMsgSendType" BO_ 288 0;
BA_ "GenMsgCycleTime" BO_ 288 10;
BA_ "GenMsgSendType" BO_ 304 0;
BA_ "GenMsgSendType" BO_ 272 0;
BA_ "GenMsgCycleTime" BO_ 272 10;
BA_ "GenSigStartValue" SG_ 293 DDC_IHv 1023;
BA_ "GenSigStartValue" SG_ 256 INV_SetILv 1023;
BA_ "GenSigStartValue" SG_ 256 INV_SetULv 128;
BA_ "GenSigStartValue" SG_ 288 DDC_ULnk 1022;
BA_ "GenSigStartValue" SG_ 288 DDC_SetULv 768;
BA_ "GenSigStartValue" SG_ 288 DDC_SetILv 1023;
BA_ "GenSigStartValue" SG_ 288 DDC_ILnk 1023;
BA_ "GenSigStartValue" SG_ 304 DDC_TempPcb 1022;
BA_ "GenSigStartValue" SG_ 304 DDC_TempDbc 1022;
BA_ "GenSigStartValue" SG_ 2046 PRM_Curr_Rect_On 5120.3277009729;
BA_ "GenSigStartValue" SG_ 2046 PRM_Curr_Rect_Off 3840.2457757296;
BA_ "GenSigStartValue" SG_ 2046 PRM_Curr_Peak_Ofs 5632.36047107;
BA_ "GenSigStartValue" SG_ 272 DDC_UC4 1023;
BA_ "GenSigStartValue" SG_ 272 DDC_ULv 1023;
BA_ "GenSigStartValue" SG_ 272 DDC_UHv 1022;
BA_ "GenSigStartValue" SG_ 272 DDC_ILv 1023;
VAL_ 293 DDC_Suc_Fail 1 "Step Up Converter is OK" 0 "Step Up Converter is NOT OK" ;
VAL_ 293 DDC_IHv 1023 "Failure" 1022 "Init" ;
VAL_ 293 DDC_UHv_Overvoltage 1 "Overvoltage is detected" 0 "No Overvoltage" ;
VAL_ 293 DDC_UHv_Undervoltage 1 "Undervoltage is detected" 0 "No Undervoltage" ;
VAL_ 293 DDC_HvOverCurrent 1 "Shutdown due to overcurrent" 0 "No overcurrent" ;
VAL_ 293 DDC_RangeChk_VZK_UBat 1 "Ok" 0 "Not Ok" ;
VAL_ 293 DDC_RangeChk_VZK_LoRng 1 "Ok" 0 "Not Ok" ;
VAL_ 293 DDC_RangeChk_VZK_HiRng 1 "Ok" 0 "Not Ok" ;
VAL_ 293 DDC_RangeChk_VZK_Gnd 1 "Ok" 0 "Not Ok" ;
VAL_ 293 DDC_RangeChk_IZK_UBat 1 "Ok" 0 "Not Ok" ;
VAL_ 293 DDC_RangeChk_IZK_LoRng 1 "Ok" 0 "Not Ok" ;
VAL_ 293 DDC_RangeChk_IZK_HiRng 1 "Ok" 0 "Not Ok" ;
VAL_ 293 DDC_RangeChk_IZK_Gnd 1 "Ok" 0 "Not Ok" ;
VAL_ 293 DDC_RangeChk_VLV_UBat 1 "Ok" 0 "Not Ok" ;
VAL_ 293 DDC_RangeChk_VLV_LoRng 1 "Ok" 0 "Not Ok" ;
VAL_ 293 DDC_RangeChk_VLV_HiRng 1 "Ok" 0 "Not Ok" ;
VAL_ 293 DDC_RangeChk_VLV_Gnd 1 "Ok" 0 "Not Ok" ;
VAL_ 293 DDC_RangeChk_VHV_UBat 1 "Ok" 0 "Not Ok" ;
VAL_ 293 DDC_RangeChk_VHV_LoRng 1 "Ok" 0 "Not Ok" ;
VAL_ 293 DDC_RangeChk_VHV_HiRng 1 "Ok" 0 "Not Ok" ;
VAL_ 293 DDC_RangeChk_VHV_Gnd 1 "Ok" 0 "Not Ok" ;
VAL_ 293 DDC_RangeChk_ILV_UBat 1 "Ok" 0 "Not Ok" ;
VAL_ 293 DDC_RangeChk_ILV_LoRng 1 "Ok" 0 "Not Ok" ;
VAL_ 293 DDC_RangeChk_ILV_HiRng 1 "Ok" 0 "Not Ok" ;
VAL_ 293 DDC_RangeChk_ILV_Gnd 1 "Ok" 0 "Not Ok" ;
VAL_ 293 DDC_RangeChk_IHV_UBat 1 "Ok" 0 "Not Ok" ;
VAL_ 293 DDC_RangeChk_IHV_LoRng 1 "Ok" 0 "Not Ok" ;
VAL_ 293 DDC_RangeChk_IHV_HiRng 1 "Ok" 0 "Not Ok" ;
VAL_ 293 DDC_RangeChk_IHV_Gnd 1 "Ok" 0 "Not Ok" ;
VAL_ 256 INV_DesMode 7 "activate Testmode" 6 "prepare Testmode" 5 "Reserved" 4 "Discharge" 3 "S9S10 Chk" 2 "GoReset" 1 "Buck" 0 "Standby" ;
VAL_ 256 INV_EnOutp 3 "EnLvOutBuck=1; EnLvOutBoost=1" 2 "EnLvOutBuck=1; EnLvOutBoost=0" 1 "EnLvOutBuck=0; EnLvOutBoost=1" 0 "EnLvOutBuck=0; EnLvOutBoost=0" ;
VAL_ 256 INV_SetILv 1023 "Failure" 1022 "Init" ;
VAL_ 256 INV_SetULv 1023 "Failure" 1022 "Init" ;
VAL_ 256 INV_TestMode 3 "Don't Care" 2 "HV test Mode" 1 "PCB Test Mode" 0 "Normal Mode" ;
VAL_ 256 INV_SucEnable 1 "turn SUC on" 0 "turn SUC off" ;
VAL_ 256 INV_UHv 1023 "Failure" 1022 "Init" ;
VAL_ 288 DDC_LiveCounter_Error 1 "Live Counter Error in INV_1" 0 "No Live Counter Error" ;
VAL_ 288 DDC_CAN_Tout 1 "CAN Time Out" 0 "No Time Out" ;
VAL_ 288 DDC_DCDC_Shutdown 3 "LVCPLD detects shutdown frm HV" 2 "HVCPLD detects shutdown frm LV" 1 "LVCPLD detects shutdown frm LVuC" 0 "Init" ;
VAL_ 288 DDC_FB_Overload 1 "FullBridge is overload" 0 "No FullBridge Overload" ;
VAL_ 288 DDC_ControlMode 1 "Current Control active" 0 "Voltage Control active" ;
VAL_ 288 DDC_HV_Serial_Data_ok 1 "Serial Data OK" 0 "Serial Data NOK" ;
VAL_ 288 DDC_LnkOverVoltage 1 "Shutdown due to overvoltage" 0 "No overvoltage" ;
VAL_ 288 DDC_LV_Serial_Data_ok 1 "Serial Data OK" 0 "Serial Data NOK" ;
VAL_ 288 DDC_ScrewExist 1 "screw exist" 0 "No screw Exist" ;
VAL_ 288 DDC_OvrTempShutDown 1 "Shutdown due to overtemperature" 0 "No overtemperature" ;
VAL_ 288 DDC_ULnk 1023 "Failure" 1022 "Init" ;
VAL_ 288 DDC_SetULv 1023 "Failure" 1022 "Init" ;
VAL_ 288 DDC_SetILv 2047 "Failure" 2046 "Init" ;
VAL_ 288 DDC_ReversePolarity 1 "Reverse Polarity" 0 "No reverse Polarity" ;
VAL_ 288 DDC_ResetFinish 1 "Tx Stdby Failure,Reset req rxd" 0 "In all other cases" ;
VAL_ 288 DDC_LV_S8_13V 1 "Supply OK" 0 "Supply not OK" ;
VAL_ 288 DDC_LV_S7_13V 1 "Supply OK" 0 "Supply not OK" ;
VAL_ 288 DDC_LV_3V3 1 "Supply OK" 0 "Supply not OK" ;
VAL_ 288 DDC_LV_13V 1 "Supply OK" 0 "Supply not OK" ;
VAL_ 288 DDC_ILnk 1023 "Failure" 1022 "Init" ;
VAL_ 288 DDC_HV_3V3 1 "Supply OK" 0 "Supply not OK" ;
VAL_ 288 DDC_HV_13V_FB 1 "Supply OK" 0 "Supply not OK" ;
VAL_ 288 DDC_HV_13V_Boost 1 "Supply OK" 0 "Supply not OK" ;
VAL_ 288 DDC_HV_13V 1 "Supply OK" 0 "Supply not OK" ;
VAL_ 288 DDC_FBEnable 1 "Full Bridge Switched on" 0 "Full Bridge Switched off" ;
VAL_ 288 DDC_SucEnable 1 "SUC Switched on" 0 "SUC Switched off" ;
VAL_ 304 DDC_RangeChk_PCB_UBat 1 "OK" 0 "NOK" ;
VAL_ 304 DDC_RangeChk_PCB_LoRng 1 "OK" 0 "NOK" ;
VAL_ 304 DDC_RangeChk_PCB_HiRng 1 "OK" 0 "NOK" ;
VAL_ 304 DDC_RangeChk_PCB_Gnd 1 "OK" 0 "NOK" ;
VAL_ 304 DDC_RangeChk_DBC_UBat 1 "OK" 0 "NOK" ;
VAL_ 304 DDC_RangeChk_DBC_LoRng 1 "OK" 0 "NOK" ;
VAL_ 304 DDC_RangeChk_DBC_HiRng 1 "OK" 0 "NOK" ;
VAL_ 304 DDC_RangeChk_DBC_Gnd 1 "OK" 0 "NOK" ;
VAL_ 304 DDC_TempPcb 1023 "Failure" 1022 "Init" ;
VAL_ 304 DDC_TempDbc 1023 "Failure" 1022 "Init" ;
VAL_ 2046 PRM_Rect_Mode 2 "Rectifier Off" 1 "Rectifier On" 0 "Rectifiermode Auto" ;
VAL_ 2046 ParameterMode 1 "Set Parameter value" 0 "Read back only" ;
VAL_ 2046 PID 9 "Rectifier mode " 8 "Rectivier limit" 7 "Deadband" 6 "Shift preset value" 5 "Current limits" 4 "Output voltage limits" 3 "Input voltage limits" 2 "Voltage control" 1 "Current control" 0 "Empty" ;
VAL_ 2017 Vari_Select_3 40 "CDR_uDCLink" 39 "CDR_uPrim2ndMeth" 38 "CDR_uOutFild" 37 "CDR_numADCUOut" 36 "CDR_iOutOfs" 35 "CDR_iOutPrimHWFilt" 34 "CDR_iOutSec" 33 "CDR_iOutFild" 32 "CDR_numDCLnkADC" 31 "CDR_iDCLnkAvrg" 30 "CDR_iDCLnkPeakFast2Fild" 29 "CTR_facCrntCtlProp" 28 "CTR_facCrntCtlIntgl" 27 "CTR_facVltgCtlProp" 26 "CTR_facVltgCtlIntgl" 25 "CTR_iInMax" 24 "CTR_uOutMax" 23 "CTR_iPeakHwLim" 22 "CTR_rICtlShft" 21 "CTR_rUCtlShft" 20 "CTR_facPriVltgCor" 19 "CTR_rShftPreCtl" 18 "CTR_rShft" 17 "CTR_iOutDem" 16 "CTR_uOutDem" 15 "CTR_rShftMax" 14 "CTR_iMinSyncRect" 13 "CTR_stElmarDrvEna" 12 "CTR_stMode" 1 "CDR_tCoolr" 11 "CDR_num15VSplyADC" 10 "CDR_u15VSply" 9 "CDR_stPcbHigh" 8 "CDR_numPcbADC" 7 "CDR_tPcb" 6 "CDR_stMosfetHigh" 5 "CDR_numMosfetADC" 4 "CDR_tMosfet" 3 "CDR_numCoolrADC" 2 "CDR_stCoolrHigh" 0 "off" ;
VAL_ 2017 Vari_Select_2 40 "CDR_uDCLink" 39 "CDR_uPrim2ndMeth" 38 "CDR_uOutFild" 37 "CDR_numADCUOut" 36 "CDR_iOutOfs" 35 "CDR_iOutPrimHWFilt" 34 "CDR_iOutSec" 33 "CDR_iOutFild" 32 "CDR_numDCLnkADC" 31 "CDR_iDCLnkAvrg" 30 "CDR_iDCLnkPeakFast2Fild" 29 "CTR_facCrntCtlProp" 28 "CTR_facCrntCtlIntgl" 27 "CTR_facVltgCtlProp" 26 "CTR_facVltgCtlIntgl" 25 "CTR_iInMax" 24 "CTR_uOutMax" 23 "CTR_iPeakHwLim" 22 "CTR_rICtlShft" 21 "CTR_rUCtlShft" 20 "CTR_facPriVltgCor" 19 "CTR_rShftPreCtl" 18 "CTR_rShft" 17 "CTR_iOutDem" 16 "CTR_uOutDem" 15 "CTR_rShftMax" 14 "CTR_iMinSyncRect" 13 "CTR_stElmarDrvEna" 12 "CTR_stMode" 1 "CDR_tCoolr" 11 "CDR_num15VSplyADC" 10 "CDR_u15VSply" 9 "CDR_stPcbHigh" 8 "CDR_numPcbADC" 7 "CDR_tPcb" 6 "CDR_stMosfetHigh" 5 "CDR_numMosfetADC" 4 "CDR_tMosfet" 3 "CDR_numCoolrADC" 2 "CDR_stCoolrHigh" 0 "off" ;
VAL_ 2017 Vari_Select_1 40 "CDR_uDCLink" 39 "CDR_uPrim2ndMeth" 38 "CDR_uOutFild" 37 "CDR_numADCUOut" 36 "CDR_iOutOfs" 35 "CDR_iOutPrimHWFilt" 34 "CDR_iOutSec" 33 "CDR_iOutFild" 32 "CDR_numDCLnkADC" 31 "CDR_iDCLnkAvrg" 30 "CDR_iDCLnkPeakFast2Fild" 29 "CTR_facCrntCtlProp" 28 "CTR_facCrntCtlIntgl" 27 "CTR_facVltgCtlProp" 26 "CTR_facVltgCtlIntgl" 25 "CTR_iInMax" 24 "CTR_uOutMax" 23 "CTR_iPeakHwLim" 22 "CTR_rICtlShft" 21 "CTR_rUCtlShft" 20 "CTR_facPriVltgCor" 19 "CTR_rShftPreCtl" 18 "CTR_rShft" 17 "CTR_iOutDem" 16 "CTR_uOutDem" 15 "CTR_rShftMax" 14 "CTR_iMinSyncRect" 13 "CTR_stElmarDrvEna" 12 "CTR_stMode" 1 "CDR_tCoolr" 11 "CDR_num15VSplyADC" 10 "CDR_u15VSply" 9 "CDR_stPcbHigh" 8 "CDR_numPcbADC" 7 "CDR_tPcb" 6 "CDR_stMosfetHigh" 5 "CDR_numMosfetADC" 4 "CDR_tMosfet" 3 "CDR_numCoolrADC" 2 "CDR_stCoolrHigh" 0 "off" ;
VAL_ 2017 Vari_Select_0 40 "CDR_uDCLink" 39 "CDR_uPrim2ndMeth" 38 "CDR_uOutFild" 37 "CDR_numADCUOut" 36 "CDR_iOutOfs" 35 "CDR_iOutPrimHWFilt" 34 "CDR_iOutSec" 33 "CDR_iOutFild" 32 "CDR_numDCLnkADC" 31 "CDR_iDCLnkAvrg" 30 "CDR_iDCLnkPeakFast2Fild" 29 "CTR_facCrntCtlProp" 28 "CTR_facCrntCtlIntgl" 27 "CTR_facVltgCtlProp" 26 "CTR_facVltgCtlIntgl" 25 "CTR_iInMax" 24 "CTR_uOutMax" 23 "CTR_iPeakHwLim" 22 "CTR_rICtlShft" 21 "CTR_rUCtlShft" 20 "CTR_facPriVltgCor" 19 "CTR_rShftPreCtl" 18 "CTR_rShft" 17 "CTR_iOutDem" 16 "CTR_uOutDem" 15 "CTR_rShftMax" 14 "CTR_iMinSyncRect" 13 "CTR_stElmarDrvEna" 12 "CTR_stMode" 1 "CDR_tCoolr" 11 "CDR_num15VSplyADC" 10 "CDR_u15VSply" 9 "CDR_stPcbHigh" 8 "CDR_numPcbADC" 7 "CDR_tPcb" 6 "CDR_stMosfetHigh" 5 "CDR_numMosfetADC" 4 "CDR_tMosfet" 3 "CDR_numCoolrADC" 2 "CDR_stCoolrHigh" 0 "off" ;
VAL_ 257 DCDC_SyncRectState 1 "Sync Rectifier On" 0 "Sync Rectifier Off" ;
VAL_ 257 DCDC_SwitchOffFault 1 "Switchoff due to fault" 0 "Not switched off due to fault" ;
VAL_ 257 DCDC_FaultPresent 1 "Fault present" 0 "No fault present" ;
VAL_ 257 DCDC__Mode 2 "Steuerung_Vorgabewert" 1 "Regelung_Aktiv" 0 "Standby" ;
VAL_ 272 DDC_UC4 1023 "Failure" 1022 "Init" ;
VAL_ 272 DDC_ULv_Plaus 1 "Low voltage plausible" 0 "Low voltage implausible" ;
VAL_ 272 DDC_EnLvOut_S9 1 "Active (closed)" 0 "Inactive (open)" ;
VAL_ 272 DDC_ShortCircuit 3 "Don't Care" 2 "Negative Short Circuit" 1 "Positive Short Circuit" 0 "No Short Circuit" ;
VAL_ 272 DDC_ILv_Sign 1 "Negative Current" 0 "Positive Current" ;
VAL_ 272 DDC_VLV_overvoltage 1 "Overvoltage Detected" 0 "No overvoltage" ;
VAL_ 272 DDC_VLV_undervoltage 1 "Undervoltage Detected" 0 "No Undervoltage" ;
VAL_ 272 DDC_ULv 1023 "Failure" 1022 "Init" ;
VAL_ 272 DDC_UHv 1023 "Failure" 1022 "Init" ;
VAL_ 272 DDC_OpMode 7 "Failure" 6 "Failure Acknowledge" 5 "Discharge" 4 "PowerBoost" 3 "S9S10 Check" 2 "Buck" 1 "Standby" 0 "Init" ;
VAL_ 272 DDC_LvOverCurrent 1 "Shutdown due to overcurrent" 0 "No overcurrent" ;
VAL_ 272 DDC_ILv 2047 "Failure" 2046 "Init" ;
VAL_ 272 DDC_EnLvOut_S10 1 "Active (closed)" 0 "Inactive (open)" ;
